# STM32MP21_CM33 register map
File version: 0.4
CPU: CM33 r0p1, little endian, MPU, FPU, vendor SysTick, 8 interrupt priority bits
Registers are 32-bit, read-write, reset 0x0 unless marked. A register's access mark holds for its fields unless they carry their own. Offsets are from the block's base; [hi:lo] are bit positions; {n}, {i} and the like mark numbered series; 'fields as' and 'values as' point back to an identical list.

## RIFSC — RIFSC register block
Base 0x42080000
Same registers: RIFSC_S 0x52080000
0x00 RIFSC_RISC_CR — RIFSC RISC slave configuration register x
  [0] GLOCK — Global lock
    0=RIFSC RISC registers are writable; 1=All writes to RIFSC RISC registers are ignored, except RIFSC_RISC_PERy_SEMCR
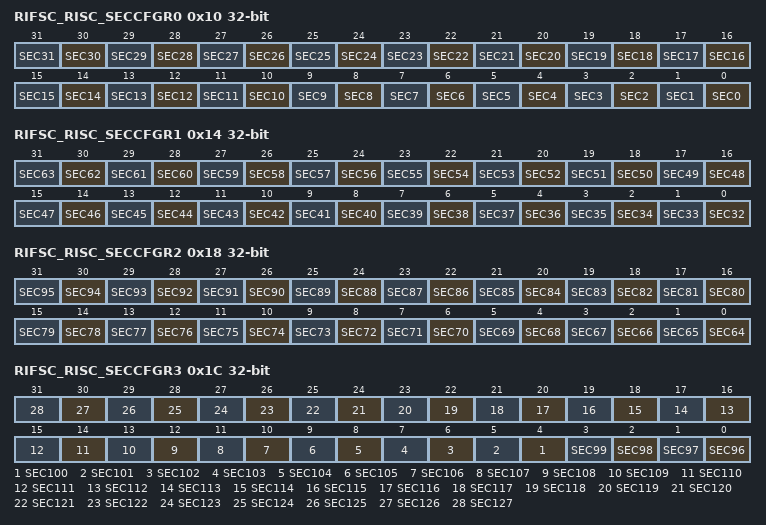
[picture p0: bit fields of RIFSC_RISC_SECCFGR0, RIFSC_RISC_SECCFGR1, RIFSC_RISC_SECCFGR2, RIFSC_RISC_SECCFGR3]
0x10 RIFSC_RISC_SECCFGR0 — RIFSC RISC slave security configuration register 0
  [n] SEC{n} (n=0..31) — Security configuration for peripheral {n}
    0=Secure and non-secure data access are granted to the peripheral {n}; 1=Secure data access only are granted to the peripheral {n}
0x14 RIFSC_RISC_SECCFGR1 — RIFSC RISC slave security configuration register 1
  [n-32] SEC{n} (n=32..63) — Security configuration for peripheral {n}
    values as RIFSC_RISC_SECCFGR0.SEC0
0x18 RIFSC_RISC_SECCFGR2 — RIFSC RISC slave security configuration register 2
  [n-64] SEC{n} (n=64..95) — Security configuration for peripheral {n}
    values as RIFSC_RISC_SECCFGR0.SEC0
0x1C RIFSC_RISC_SECCFGR3 — RIFSC RISC slave security configuration register 3
  [n-96] SEC{n} (n=96..127) — Security configuration for peripheral {n}
    values as RIFSC_RISC_SECCFGR0.SEC0
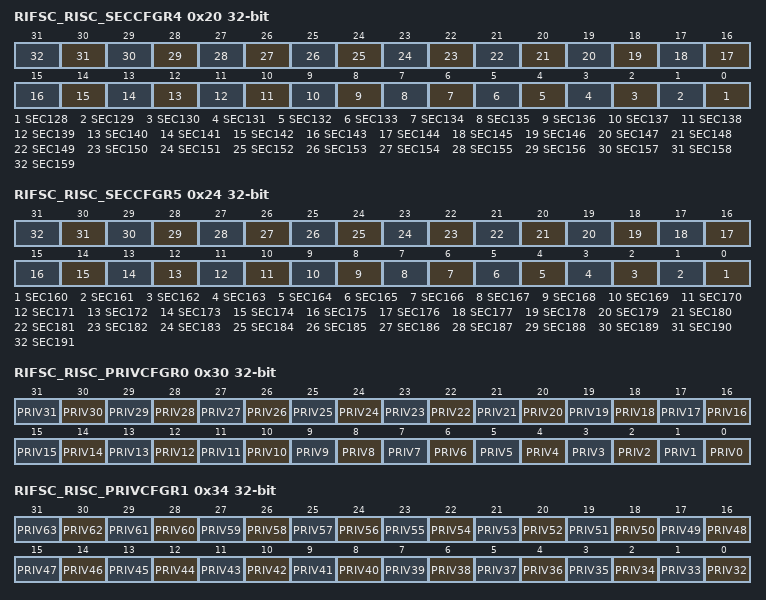
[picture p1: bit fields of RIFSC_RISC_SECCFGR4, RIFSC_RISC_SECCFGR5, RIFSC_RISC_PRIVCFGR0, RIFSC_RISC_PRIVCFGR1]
0x20 RIFSC_RISC_SECCFGR4 — RIFSC RISC slave security configuration register 4
  [n-128] SEC{n} (n=128..159) — Security configuration for peripheral {n}
    values as RIFSC_RISC_SECCFGR0.SEC0
0x24 RIFSC_RISC_SECCFGR5 — RIFSC RISC slave security configuration register 5
  [n-160] SEC{n} (n=160..191) — Security configuration for peripheral {n}
    values as RIFSC_RISC_SECCFGR0.SEC0
0x30 RIFSC_RISC_PRIVCFGR0 — RIFSC RISFC slave privileged register 0
  [n] PRIV{n} (n=0..31) — Privileged-only access permission for peripheral {n}
    0=Privileged and unprivileged data access are granted to the peripheral {n}; 1=Privileged data access only are granted to the peripheral {n}
0x34 RIFSC_RISC_PRIVCFGR1 — RIFSC RISFC slave privileged register 1
  [n-32] PRIV{n} (n=32..63) — Privileged-only access permission for peripheral {n}
    values as RIFSC_RISC_PRIVCFGR0.PRIV0
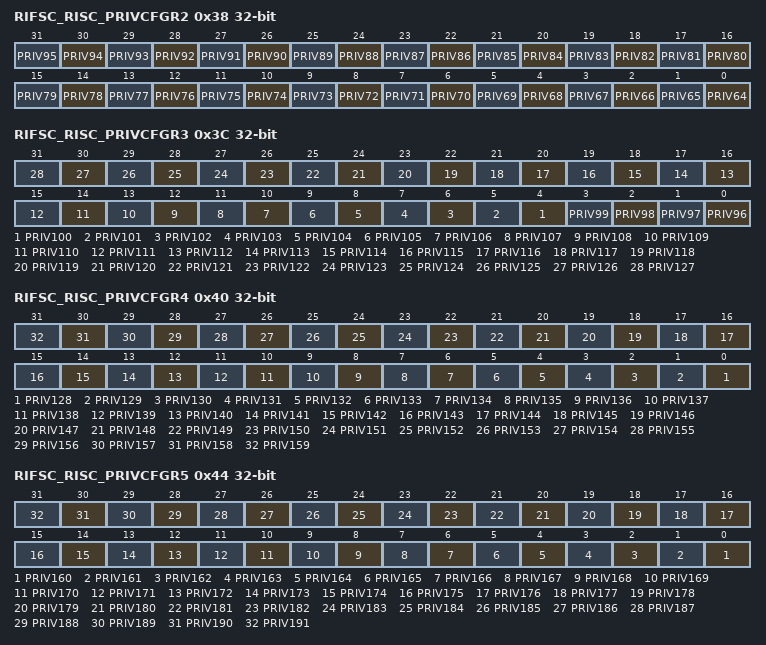
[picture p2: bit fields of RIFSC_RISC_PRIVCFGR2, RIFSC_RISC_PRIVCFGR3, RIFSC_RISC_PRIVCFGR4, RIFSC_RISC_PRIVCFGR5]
0x38 RIFSC_RISC_PRIVCFGR2 — RIFSC RISFC slave privileged register 2
  [n-64] PRIV{n} (n=64..95) — Privileged-only access permission for peripheral {n}
    values as RIFSC_RISC_PRIVCFGR0.PRIV0
0x3C RIFSC_RISC_PRIVCFGR3 — RIFSC RISFC slave privileged register 3
  [n-96] PRIV{n} (n=96..127) — Privileged-only access permission for peripheral {n}
    values as RIFSC_RISC_PRIVCFGR0.PRIV0
0x40 RIFSC_RISC_PRIVCFGR4 — RIFSC RISFC slave privileged register 4
  [n-128] PRIV{n} (n=128..159) — Privileged-only access permission for peripheral {n}
    values as RIFSC_RISC_PRIVCFGR0.PRIV0
0x44 RIFSC_RISC_PRIVCFGR5 — RIFSC RISFC slave privileged register 5
  [n-160] PRIV{n} (n=160..191) — Privileged-only access permission for peripheral {n}
    values as RIFSC_RISC_PRIVCFGR0.PRIV0
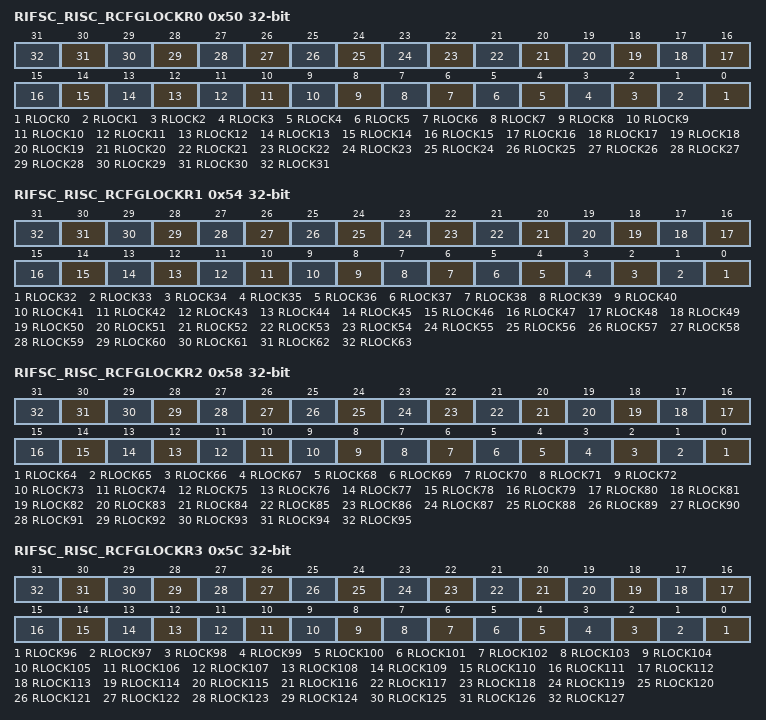
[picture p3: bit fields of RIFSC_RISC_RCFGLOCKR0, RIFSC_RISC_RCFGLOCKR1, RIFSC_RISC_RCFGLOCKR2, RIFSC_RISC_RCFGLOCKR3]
0x50 RIFSC_RISC_RCFGLOCKR0 — RIFSC RISC slave resource configuration lock register 0
  [n] RLOCK{n} (n=0..31) — rRsource lock for peripheral {n}
    0=SEC{n} in RIFSC_RISC_SECCFGRx and PRIV{n}; 1=Writes to SEC{n} and PRIV{n} are ignored
0x54 RIFSC_RISC_RCFGLOCKR1 — RIFSC RISC slave resource configuration lock register 1
  [n-32] RLOCK{n} (n=32..63) — rRsource lock for peripheral {n}
    values as RIFSC_RISC_RCFGLOCKR0.RLOCK0
0x58 RIFSC_RISC_RCFGLOCKR2 — RIFSC RISC slave resource configuration lock register 2
  [n-64] RLOCK{n} (n=64..95) — rRsource lock for peripheral {n}
    values as RIFSC_RISC_RCFGLOCKR0.RLOCK0
0x5C RIFSC_RISC_RCFGLOCKR3 — RIFSC RISC slave resource configuration lock register 3
  [n-96] RLOCK{n} (n=96..127) — rRsource lock for peripheral {n}
    values as RIFSC_RISC_RCFGLOCKR0.RLOCK0
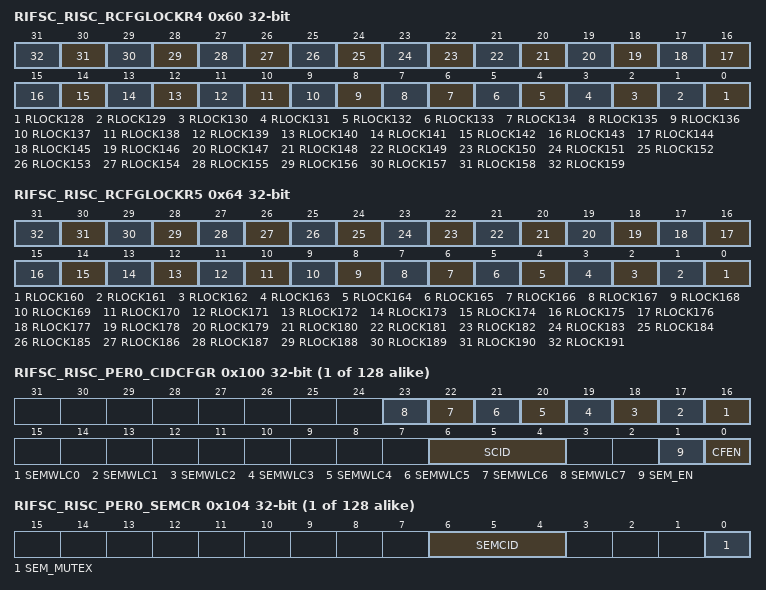
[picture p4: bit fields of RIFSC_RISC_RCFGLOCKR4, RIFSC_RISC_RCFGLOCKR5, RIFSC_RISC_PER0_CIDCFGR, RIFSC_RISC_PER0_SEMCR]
0x60 RIFSC_RISC_RCFGLOCKR4 — RIFSC RISC slave resource configuration lock register 4
  [n-128] RLOCK{n} (n=128..159) — rRsource lock for peripheral {n}
    values as RIFSC_RISC_RCFGLOCKR0.RLOCK0
0x64 RIFSC_RISC_RCFGLOCKR5 — RIFSC RISC slave resource configuration lock register 5
  [n-160] RLOCK{n} (n=160..191) — rRsource lock for peripheral {n}
    values as RIFSC_RISC_RCFGLOCKR0.RLOCK0
{0x100+8i} RIFSC_RISC_PER{i}_CIDCFGR (i=0..127) — RIFSC RISC slave peripheral {i} CID configuration register
  [n+16] SEMWLC{n} (n=0..7) — Semaphore white list for compartment i
    0=Application running in compartment i cannot get access to peripheral y through the semaphore SEM_MUTEX; 1=Application running in compartment i can get access to peripheral y through the semaphore SEM_MUTEX
  [6:4] SCID — Static CID
  [1] SEM_EN — Semaphore enable
    0=Access to peripheral y is granted only if CID of the access equals to SCID; 1=Access to peripheral y is granted only if SEM_MUTEX = 1 and CID of the access equals
  [0] CFEN — CID filtering enable
    0=Compartment-based filtering defined in RIFSC_RISC_PERy_CIDCFGR and optionally RIFSC_RISC_PERy_SEMCR is disabled for peripheral y; 1=Compartment-based filtering defined in RIFSC_RISC_PERy_CIDCFGR and optionally RIFSC_RISC_PERy_SEMCR is enabled for peripheral y
{0x104+8i} RIFSC_RISC_PER{i}_SEMCR (i=0..127) — RIFSC RISC slave peripheral {i} semaphore control register
  [6:4] SEMCID ro — Semaphore current CID
  [0] SEM_MUTEX — Semaphore mutex
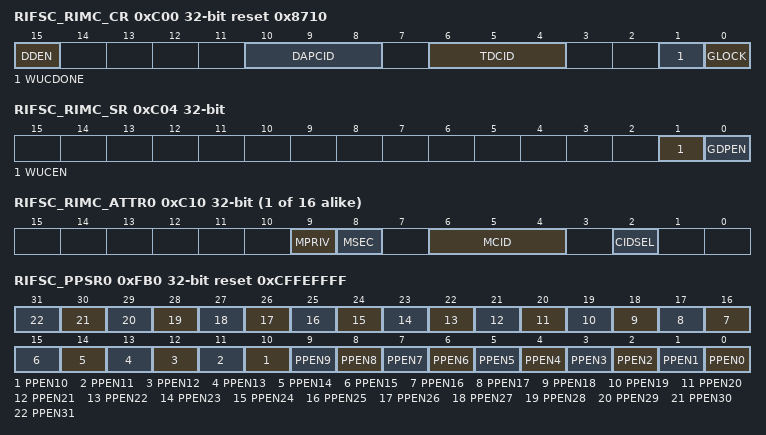
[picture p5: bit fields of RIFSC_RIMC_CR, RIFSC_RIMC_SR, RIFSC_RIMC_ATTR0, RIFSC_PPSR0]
0xC00 RIFSC_RIMC_CR rw-once reset 0x8710 — RIFSC RIMC master configuration register
  [15] DDEN ro — Debug domain enable
    0=Debug domain not available; 1=Debug domain available
  [10:8] DAPCID rw — Debug access port compartment ID
  [6:4] TDCID — Trusted domain compartment ID
  [1] WUCDONE rw — Wake-up CPU done
    0=When WUCEN = 1 in RIFSC_RIMC_SR, the trusted domain CID information is fixed to0x2 (wake-up CPU), else it is defined in this register; 1=Setting this bit clears WUCEN after few cycles
  [0] GLOCK rw — Global lock
    0=RIFSC RIMC registers are writable; 1=All writes to RIFSC RIMC registers are ignored
0xC04 RIFSC_RIMC_SR ro — RIFSC RIMC master status register
  [1] WUCEN — Wake-up CPU enable
    0=Wake-up CPU is disabled; 1=Wake-up CPU is enabled
  [0] GDPEN — Global debug profile enable
    0=Global-debug profile (CPU + MCU) is not activated; 1=Global-debug profile (CPU + MCU) is activated
{0xC10+4i} RIFSC_RIMC_ATTR{i} (i=0..15) — RIFSC RIMC master attribute register {i}
  [9] MPRIV — Master privileged
    0=This master is unprivileged; 1=This master is privileged
  [8] MSEC — Master secure
    0=This master is non-secure; 1=This master is secure
  [6:4] MCID — Master CID
  [2] CIDSEL — CID selection
    0=Compartment ID of master x is driven by hardware value or by inheritance to associated RISUP; 1=Compartment ID of master x is defined by MCID[2:0] in this register
0xFB0 RIFSC_PPSR0 ro reset 0xCFFEFFFF — RIFSC peripheral protection status register 0
  [n] PPEN{n} (n=0..31) — Peripheral protection enable {n}
    0=RISUP protection to peripheral {n} is not present; 1=RISUP protection to peripheral {n} is present
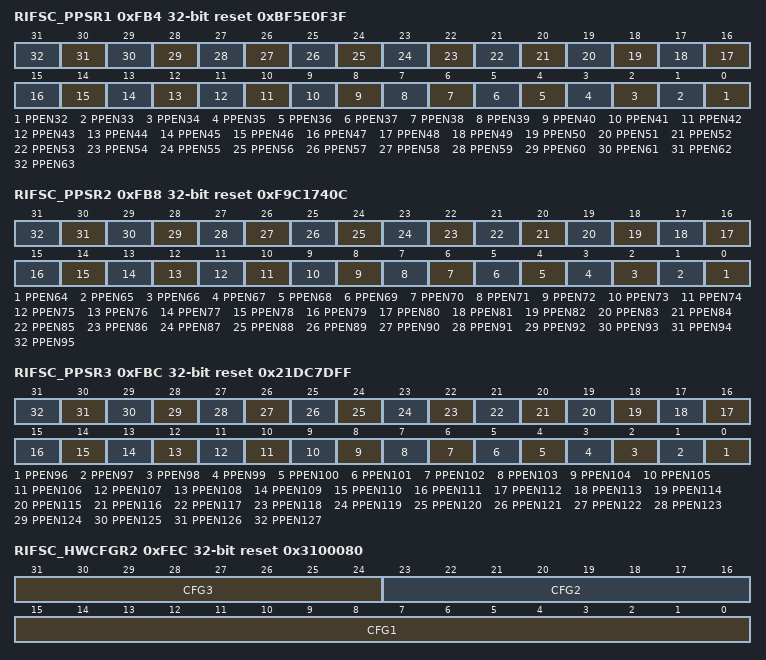
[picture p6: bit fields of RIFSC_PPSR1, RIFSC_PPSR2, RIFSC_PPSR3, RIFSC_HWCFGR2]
0xFB4 RIFSC_PPSR1 ro reset 0xBF5E0F3F — RIFSC peripheral protection status register 1
  [n-32] PPEN{n} (n=32..63) — Peripheral protection enable {n}
    values as RIFSC_PPSR0.PPEN0
0xFB8 RIFSC_PPSR2 ro reset 0xF9C1740C — RIFSC peripheral protection status register 2
  [n-64] PPEN{n} (n=64..95) — Peripheral protection enable {n}
    values as RIFSC_PPSR0.PPEN0
0xFBC RIFSC_PPSR3 ro reset 0x21DC7DFF — RIFSC peripheral protection status register 3
  [n-96] PPEN{n} (n=96..127) — Peripheral protection enable {n}
    values as RIFSC_PPSR0.PPEN0
0xFE8 RIFSC_HWCFGR3 ro reset 0x3 — RIFSC hardware configuration register 3
  [31:0] CFG — Hardware configuration
0xFEC RIFSC_HWCFGR2 ro reset 0x3100080 — RIFSC hardware configuration register 2
  [31:24] CFG3 — Hardware configuration 3
  [23:16] CFG2 — Hardware configuration 2
  [15:0] CFG1 — Hardware configuration 1
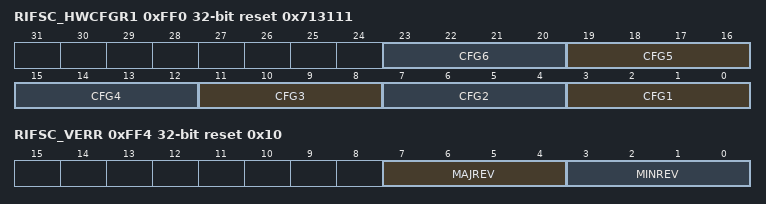
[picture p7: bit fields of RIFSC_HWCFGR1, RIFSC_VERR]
0xFF0 RIFSC_HWCFGR1 ro reset 0x713111 — RIFSC hardware configuration register 1
  [4n-1:4n-4] CFG{n} (n=1..6) — Hardware configuration {n}
0xFF4 RIFSC_VERR ro reset 0x10 — RIFSC version register
  [7:4] MAJREV — RIFSC major revision
  [3:0] MINREV — RIFSC minor revision
0xFF8 RIFSC_IPIDR ro reset 0x100162 — RIFSC identification register
  [31:0] ID — RIFSC identification code
0xFFC RIFSC_SIDR ro reset 0xA3C5DD04 — RIFSC size identification register
  [31:0] SID — RIFSC size identification code
